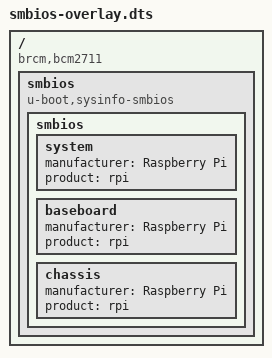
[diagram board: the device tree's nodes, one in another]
/dts-v1/;
/plugin/;

/ {
	compatible = "brcm,bcm2711";

	fragment@0 {
		target-path = "/";
		__overlay__ {

			smbios {
				compatible = "u-boot,sysinfo-smbios";
				smbios {
					system {
						manufacturer = "Raspberry Pi";
						product = "rpi";
					};
					baseboard {
						manufacturer = "Raspberry Pi";
						product = "rpi";
					};
					chassis {
						manufacturer = "Raspberry Pi";
						product = "rpi";
					};
				};
			};
		};
	};
};

